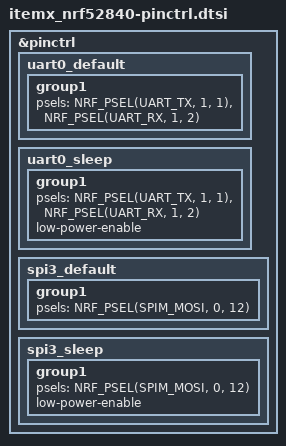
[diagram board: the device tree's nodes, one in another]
/*
 * SPDX-License-Identifier: Apache-2.0
 *
 * Pin control for ITEMX board (nRF52840)
 * SPI3 is used to drive the SK6805 LED strip via MOSI on P0.12
 * (matches the official ZMK nRF52 RGB underglow example)
 */

&pinctrl {
	uart0_default: uart0_default {
		group1 {
			psels = <NRF_PSEL(UART_TX, 1, 1)>, <NRF_PSEL(UART_RX, 1, 2)>;
		};
	};

	uart0_sleep: uart0_sleep {
		group1 {
			psels = <NRF_PSEL(UART_TX, 1, 1)>, <NRF_PSEL(UART_RX, 1, 2)>;
			low-power-enable;
		};
	};

	spi3_default: spi3_default {
		group1 {
			psels = <NRF_PSEL(SPIM_MOSI, 0, 12)>;
		};
	};

	spi3_sleep: spi3_sleep {
		group1 {
			psels = <NRF_PSEL(SPIM_MOSI, 0, 12)>;
			low-power-enable;
		};
	};
};
